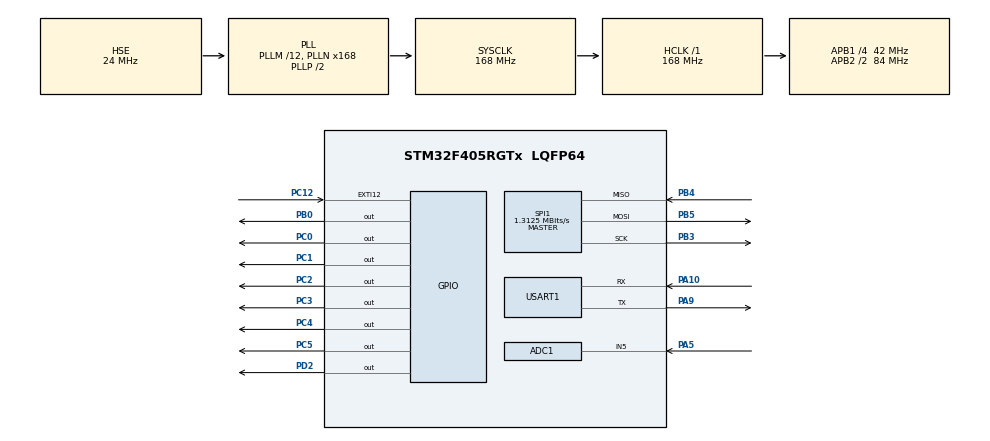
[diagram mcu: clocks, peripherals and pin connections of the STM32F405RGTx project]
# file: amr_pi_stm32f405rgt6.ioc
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ADC1.Channel-0\#ChannelRegularConversion=ADC_CHANNEL_5
ADC1.NbrOfConversionFlag=1
ADC1.Rank-0\#ChannelRegularConversion=1
ADC1.SamplingTime-0\#ChannelRegularConversion=ADC_SAMPLETIME_3CYCLES
ADC1.master=1
Mcu.Family=STM32F4
Mcu.Name=STM32F405RGTx
Mcu.Package=LQFP64
NVIC.PriorityGroup=NVIC_PRIORITYGROUP_4
PA0-WKUP.Signal=S_TIM5_CH1
PA1.Signal=S_TIM5_CH2
PA10.Mode=Asynchronous
PA10.Signal=USART1_RX
PA11.Signal=USB_OTG_FS_DM
PA12.Signal=USB_OTG_FS_DP
PA13.Signal=SYS_JTMS-SWDIO
PA14.Signal=SYS_JTCK-SWCLK
PA2.Signal=USART2_TX
PA3.Signal=USART2_RX
PA5.Signal=ADCx_IN5
PA6.Signal=S_TIM3_CH1
PA7.Signal=S_TIM3_CH2
PA9.Mode=Asynchronous
PA9.Signal=USART1_TX
PB0.Signal=GPIO_Output
PB10.Signal=S_TIM2_CH3
PB11.Signal=S_TIM2_CH4
PB3.Mode=Full_Duplex_Master
PB3.Signal=SPI1_SCK
PB4.Mode=Full_Duplex_Master
PB4.Signal=SPI1_MISO
PB5.Mode=Full_Duplex_Master
PB5.Signal=SPI1_MOSI
PB6.Signal=I2C1_SCL
PB7.Signal=I2C1_SDA
PC0.Signal=GPIO_Output
PC1.Signal=GPIO_Output
PC10.Signal=USART3_TX
PC11.Signal=USART3_RX
PC12.Signal=GPXTI12
PC2.Signal=GPIO_Output
PC3.Signal=GPIO_Output
PC4.Signal=GPIO_Output
PC5.Signal=GPIO_Output
PD2.GPIO_Speed=GPIO_SPEED_FREQ_VERY_HIGH
PD2.Signal=GPIO_Output
PH0-OSC_IN.Mode=HSE-External-Oscillator
PH0-OSC_IN.Signal=RCC_OSC_IN
PH1-OSC_OUT.Mode=HSE-External-Oscillator
PH1-OSC_OUT.Signal=RCC_OSC_OUT
ProjectManager.HeapSize=0x200
ProjectManager.StackSize=0x400
ProjectManager.TargetToolchain=STM32CubeIDE
RCC.48MHZClocksFreq_Value=84000000
RCC.AHBFreq_Value=168000000
RCC.APB1CLKDivider=RCC_HCLK_DIV4
RCC.APB1Freq_Value=42000000
RCC.APB1TimFreq_Value=84000000
RCC.APB2CLKDivider=RCC_HCLK_DIV2
RCC.APB2Freq_Value=84000000
RCC.APB2TimFreq_Value=168000000
RCC.CortexFreq_Value=168000000
RCC.HCLKFreq_Value=168000000
RCC.HSE_VALUE=24000000
RCC.HSI_VALUE=16000000
RCC.LSE_VALUE=32768
RCC.PLLM=12
RCC.PLLN=168
RCC.PLLSourceVirtual=RCC_PLLSOURCE_HSE
RCC.SYSCLKFreq_VALUE=168000000
RCC.SYSCLKSource=RCC_SYSCLKSOURCE_PLLCLK
RCC.VCOOutputFreq_Value=336000000
SH.ADCx_IN5.0=ADC1_IN5,IN5
SH.S_TIM2_CH3.0=TIM2_CH3
SH.S_TIM2_CH4.0=TIM2_CH4
SH.S_TIM3_CH1.0=TIM3_CH1
SH.S_TIM3_CH2.0=TIM3_CH2
SH.S_TIM5_CH1.0=TIM5_CH1
SH.S_TIM5_CH2.0=TIM5_CH2
SPI1.BaudRatePrescaler=SPI_BAUDRATEPRESCALER_64
SPI1.CalculateBaudRate=1.3125 MBits/s
SPI1.Direction=SPI_DIRECTION_2LINES
SPI1.Mode=SPI_MODE_MASTER
SPI1.VirtualType=VM_MASTER
USART1.VirtualMode=VM_ASYNC
board=custom

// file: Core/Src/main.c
/* USER CODE BEGIN Header */
/**
  ******************************************************************************
  * @file           : main.c
  * @brief          : Main program body
  ******************************************************************************
  */
/* USER CODE END Header */
#include "main.h"
#include "adc.h"
#include "spi.h"
#include "usart.h"
#include "gpio.h"

/* USER CODE BEGIN Includes */
#include "sensor_imu.h"
/* USER CODE END Includes */

void SystemClock_Config(void);

int main(void)
{
  /* MCU Configuration--------------------------------------------------------*/

  /* Reset of all peripherals, Initializes the Flash interface and the Systick. */
  HAL_Init();

  /* Configure the system clock */
  SystemClock_Config();

  /* Initialize all configured peripherals */
  MX_GPIO_Init();
  MX_ADC1_Init();
  MX_SPI1_Init();
  MX_USART1_UART_Init();

  /* USER CODE BEGIN 2 */

  // Khởi tạo SPI và cấu hình cảm biến BMI323
  IMU_Init();

  /* USER CODE END 2 */

  /* Infinite loop */
    /* USER CODE BEGIN WHILE */
    while (1)
    {
        // Cập nhật dữ liệu từ cảm biến
        IMU_Read_Data();
        // Chờ 10ms
        HAL_Delay(10);

      /* USER CODE END WHILE */
    }
}

void SystemClock_Config(void)
{
  RCC_OscInitTypeDef RCC_OscInitStruct = {0};
  RCC_ClkInitTypeDef RCC_ClkInitStruct = {0};

  __HAL_RCC_PWR_CLK_ENABLE();
  __HAL_PWR_VOLTAGESCALING_CONFIG(PWR_REGULATOR_VOLTAGE_SCALE1);

  RCC_OscInitStruct.OscillatorType = RCC_OSCILLATORTYPE_HSE;
  RCC_OscInitStruct.HSEState = RCC_HSE_ON;
  RCC_OscInitStruct.PLL.PLLState = RCC_PLL_ON;
  RCC_OscInitStruct.PLL.PLLSource = RCC_PLLSOURCE_HSE;
  RCC_OscInitStruct.PLL.PLLM = 12;
  RCC_OscInitStruct.PLL.PLLN = 168;
  RCC_OscInitStruct.PLL.PLLP = RCC_PLLP_DIV2;
  RCC_OscInitStruct.PLL.PLLQ = 4;
  if (HAL_RCC_OscConfig(&RCC_OscInitStruct) != HAL_OK)
  {
    Error_Handler();
  }

  RCC_ClkInitStruct.ClockType = RCC_CLOCKTYPE_HCLK|RCC_CLOCKTYPE_SYSCLK
                              |RCC_CLOCKTYPE_PCLK1|RCC_CLOCKTYPE_PCLK2;
  RCC_ClkInitStruct.SYSCLKSource = RCC_SYSCLKSOURCE_PLLCLK;
  RCC_ClkInitStruct.AHBCLKDivider = RCC_SYSCLK_DIV1;
  RCC_ClkInitStruct.APB1CLKDivider = RCC_HCLK_DIV4;
  RCC_ClkInitStruct.APB2CLKDivider = RCC_HCLK_DIV2;

  if (HAL_RCC_ClockConfig(&RCC_ClkInitStruct, FLASH_LATENCY_5) != HAL_OK)
  {
    Error_Handler();
  }
}

void Error_Handler(void)
{
  /* USER CODE BEGIN Error_Handler_Debug */
  __disable_irq();
  HAL_GPIO_WritePin(GPIOC, GPIO_PIN_4, GPIO_PIN_SET);
  while (1)
  {
  }
  /* USER CODE END Error_Handler_Debug */
}
